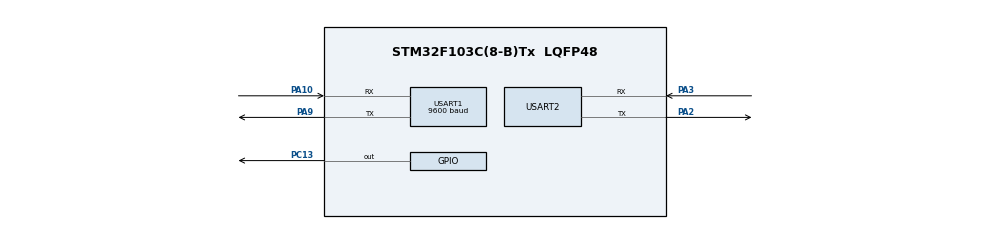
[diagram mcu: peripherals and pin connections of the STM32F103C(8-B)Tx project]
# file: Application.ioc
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Mcu.Family=STM32F1
Mcu.Name=STM32F103C(8-B)Tx
Mcu.Package=LQFP48
NVIC.PriorityGroup=NVIC_PRIORITYGROUP_4
NVIC.USART1_IRQn=true\:0\:0\:false\:false\:true\:true\:true\:true
PA10.Mode=Asynchronous
PA10.Signal=USART1_RX
PA13.Mode=Serial_Wire
PA13.Signal=SYS_JTMS-SWDIO
PA14.Mode=Serial_Wire
PA14.Signal=SYS_JTCK-SWCLK
PA2.Mode=Asynchronous
PA2.Signal=USART2_TX
PA3.Mode=Asynchronous
PA3.Signal=USART2_RX
PA9.Mode=Asynchronous
PA9.Signal=USART1_TX
PC13-TAMPER-RTC.Signal=GPIO_Output
ProjectManager.HeapSize=0x200
ProjectManager.StackSize=0x400
ProjectManager.TargetToolchain=CMake
RCC.APB1Freq_Value=8000000
RCC.APB2Freq_Value=8000000
USART1.BaudRate=9600
USART1.VirtualMode=VM_ASYNC
USART2.VirtualMode=VM_ASYNC
board=custom

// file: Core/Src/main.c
/* USER CODE BEGIN Header */
/**
 ******************************************************************************
 * @file           : main.c
 * @brief          : Main program body
 ******************************************************************************
 * @attention
 *
 * Copyright (c) 2025 STMicroelectronics.
 * All rights reserved.
 *
 * This software is licensed under terms that can be found in the LICENSE file
 * in the root directory of this software component.
 * If no LICENSE file comes with this software, it is provided AS-IS.
 *
 ******************************************************************************
 */
/* USER CODE END Header */
#include "main.h"
#include <stdio.h>
#include <string.h>
#include "crc16.h"

#define MAJOR 1
#define MINOR 1
#define BUILD 0

#define MAX_UART1_RX_BUFF 256
#define MAX_UART1_TX_BUFF 32

UART_HandleTypeDef huart1;
UART_HandleTypeDef huart2;
uint8_t rx[MAX_UART1_RX_BUFF];
uint8_t tx[MAX_UART1_TX_BUFF];

static uint8_t volatile rxIdx;
static uint8_t volatile rxByte;
uint8_t resetFlag = 0;
/* USER CODE BEGIN PV */
uint8_t ApplicationVersion[3] = {MAJOR, MINOR, BUILD};
/* USER CODE END PV */
// CRC-16/IBM-3740
// const uint8_t reset_command[] = {0xac, 0x02, 0x00, 0x01, 0x37, 0x4D};

#ifdef __GNUC__
/* With GCC, small printf (option LD Linker->Libraries->Small printf
   set to 'Yes') calls __io_putchar() */
int __io_putchar(int ch)
#else
int fputc(int ch, FILE *f)
#endif /* __GNUC__ */
{
  /* Place your implementation of fputc here */
  /* e.g. write a character to the UART3 and Loop until the end of transmission */
  HAL_UART_Transmit(&huart2, (uint8_t *)&ch, 1, HAL_MAX_DELAY);

  return ch;
}

void SystemClock_Config(void);
static void MX_GPIO_Init(void);
static void MX_USART1_UART_Init(void);
static void MX_USART2_UART_Init(void);

void Start_UART_IT()
{
  HAL_UART_Receive_IT(&huart1, (uint8_t *)&rxByte, 1); // Nhận từng byte một bằng ngắt
}

void HAL_UART_RxCpltCallback(UART_HandleTypeDef *huart)
{
  if (huart == &huart1)
  {
    rx[rxIdx++] = rxByte;
    HAL_UART_Receive_IT(&huart1, (uint8_t *)&rxByte, 1);
  }
}

static volatile uint8_t rxGetIdx = 0;
static uint8_t parseState = 0;
static uint8_t lengthPck = 0;
static uint8_t remainDataByte;
uint16_t crc;

void package_parse()
{
  if (rxIdx > 0 && rxGetIdx < rxIdx)
  {
    switch (parseState)
    {
    case START_BYTE:
      printf("START_BYTE \r\n");
      if (rx[rxGetIdx] == 0xAC)
      {
        parseState = LENGTH_BYTE;
      }
      break;
    case LENGTH_BYTE:

      lengthPck = rx[rxGetIdx];
      parseState = CMD_BYTE;
      remainDataByte = lengthPck;
      printf("LENGTH_BYTE %d\r\n", lengthPck);
      break;

    case CMD_BYTE:
      if (rx[rxGetIdx] == RESET_CMD)
      {
        resetFlag = 1;
      }
      parseState = DATA_BYTE;
      remainDataByte--;
      break;

    case DATA_BYTE:
      remainDataByte--;
      printf("DATA_BYTE %d\r\n", remainDataByte);
      if (remainDataByte <= 0)
      {
        parseState = CRC1_BYTE;
      }
      break;

    case CRC1_BYTE:
      printf("CRC1_BYTE\r\n");
      parseState = CRC2_BYTE;
      break;

    case CRC2_BYTE:
      printf("CRC2_BYTE\r\n");
      crc = crc_16((const unsigned char *)&rx[rxGetIdx - 1 - lengthPck], lengthPck + 1);
      if ((crc & 0xff) == rx[rxGetIdx] && ((crc >> 8) & 0xff) == rx[rxGetIdx - 1])
      {

        printf("success crc\r\n");
      }
      else
      {
        printf("Error crc\r\n");
      }

      rxGetIdx = 0;
      parseState = 0;
      lengthPck = 0;
      remainDataByte = 0;
      rxIdx =0;
      parseState = START_BYTE;
      break;

    default:
      break;
    }
    rxGetIdx++;
  }
}

int main(void)
{

  /* MCU Configuration--------------------------------------------------------*/

  /* Reset of all peripherals, Initializes the Flash interface and the Systick. */
  HAL_Init();

  /* Configure the system clock */
  SystemClock_Config();

  /* Initialize all configured peripherals */
  MX_GPIO_Init();
  MX_USART1_UART_Init();
  MX_USART2_UART_Init();
  /* USER CODE BEGIN 2 */
  printf("Application %d.%d.%d Started!!!\n", ApplicationVersion[0], ApplicationVersion[1], ApplicationVersion[2]);
  Start_UART_IT();
  /* USER CODE END 2 */
  uint32_t time1 = HAL_GetTick();

  while (1)
  {
    // Blink 1
    if (HAL_GetTick() - time1 > 500)
    {
      time1 = HAL_GetTick();
      HAL_GPIO_TogglePin(GPIOC, GPIO_PIN_13);
    }
    package_parse();
    if(resetFlag ==1 ){
      printf("Reset chip\r\n");
      NVIC_SystemReset();
    }
  }
}

void SystemClock_Config(void)
{
  RCC_OscInitTypeDef RCC_OscInitStruct = {0};
  RCC_ClkInitTypeDef RCC_ClkInitStruct = {0};

  /** Initializes the RCC Oscillators according to the specified parameters
  * in the RCC_OscInitTypeDef structure.
  */
  RCC_OscInitStruct.OscillatorType = RCC_OSCILLATORTYPE_HSI;
  RCC_OscInitStruct.HSIState = RCC_HSI_ON;
  RCC_OscInitStruct.HSICalibrationValue = RCC_HSICALIBRATION_DEFAULT;
  RCC_OscInitStruct.PLL.PLLState = RCC_PLL_NONE;
  if (HAL_RCC_OscConfig(&RCC_OscInitStruct) != HAL_OK)
  {
    Error_Handler();
  }

  /** Initializes the CPU, AHB and APB buses clocks
  */
  RCC_ClkInitStruct.ClockType = RCC_CLOCKTYPE_HCLK|RCC_CLOCKTYPE_SYSCLK
                              |RCC_CLOCKTYPE_PCLK1|RCC_CLOCKTYPE_PCLK2;
  RCC_ClkInitStruct.SYSCLKSource = RCC_SYSCLKSOURCE_HSI;
  RCC_ClkInitStruct.AHBCLKDivider = RCC_SYSCLK_DIV1;
  RCC_ClkInitStruct.APB1CLKDivider = RCC_HCLK_DIV1;
  RCC_ClkInitStruct.APB2CLKDivider = RCC_HCLK_DIV1;

  if (HAL_RCC_ClockConfig(&RCC_ClkInitStruct, FLASH_LATENCY_0) != HAL_OK)
  {
    Error_Handler();
  }
}

static void MX_USART1_UART_Init(void)
{

  huart1.Instance = USART1;
  huart1.Init.BaudRate = 115200;
  huart1.Init.WordLength = UART_WORDLENGTH_8B;
  huart1.Init.StopBits = UART_STOPBITS_1;
  huart1.Init.Parity = UART_PARITY_NONE;
  huart1.Init.Mode = UART_MODE_TX_RX;
  huart1.Init.HwFlowCtl = UART_HWCONTROL_NONE;
  huart1.Init.OverSampling = UART_OVERSAMPLING_16;
  if (HAL_UART_Init(&huart1) != HAL_OK)
  {
    Error_Handler();
  }

}

static void MX_USART2_UART_Init(void)
{

  huart2.Instance = USART2;
  huart2.Init.BaudRate = 115200;
  huart2.Init.WordLength = UART_WORDLENGTH_8B;
  huart2.Init.StopBits = UART_STOPBITS_1;
  huart2.Init.Parity = UART_PARITY_NONE;
  huart2.Init.Mode = UART_MODE_TX_RX;
  huart2.Init.HwFlowCtl = UART_HWCONTROL_NONE;
  huart2.Init.OverSampling = UART_OVERSAMPLING_16;
  if (HAL_UART_Init(&huart2) != HAL_OK)
  {
    Error_Handler();
  }

}

static void MX_GPIO_Init(void)
{
  GPIO_InitTypeDef GPIO_InitStruct = {0};

  /* GPIO Ports Clock Enable */
  __HAL_RCC_GPIOC_CLK_ENABLE();
  __HAL_RCC_GPIOA_CLK_ENABLE();

  /*Configure GPIO pin Output Level */
  HAL_GPIO_WritePin(GPIOC, GPIO_PIN_13, GPIO_PIN_RESET);

  /*Configure GPIO pin : PC13 */
  GPIO_InitStruct.Pin = GPIO_PIN_13;
  GPIO_InitStruct.Mode = GPIO_MODE_OUTPUT_PP;
  GPIO_InitStruct.Pull = GPIO_NOPULL;
  GPIO_InitStruct.Speed = GPIO_SPEED_FREQ_LOW;
  HAL_GPIO_Init(GPIOC, &GPIO_InitStruct);

}

void Error_Handler(void)
{
  __disable_irq();
  while (1)
  {
  }
}
